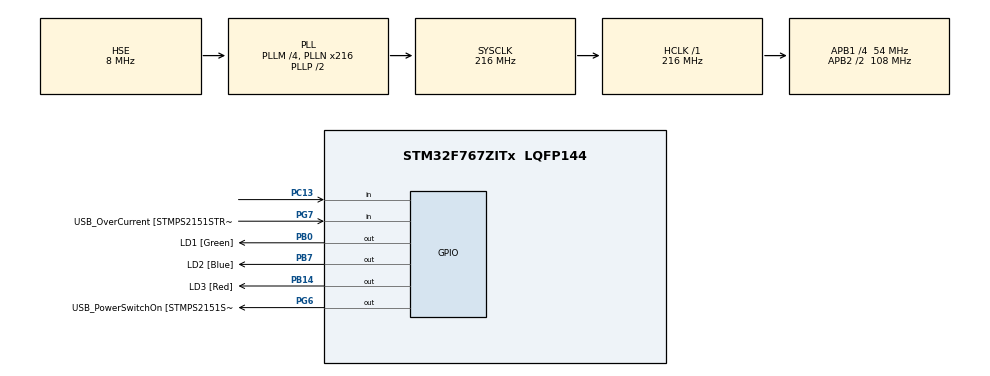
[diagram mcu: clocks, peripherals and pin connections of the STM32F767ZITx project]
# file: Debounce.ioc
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Mcu.Family=STM32F7
Mcu.Name=STM32F767ZITx
Mcu.Package=LQFP144
NVIC.PriorityGroup=NVIC_PRIORITYGROUP_4
NVIC.TIM6_DAC_IRQn=true\:0\:0\:false\:false\:true\:true\:true
PA13.GPIO_Label=TMS
PA13.Mode=Serial_Wire
PA13.Signal=SYS_JTMS-SWDIO
PA14.GPIO_Label=TCK
PA14.Mode=Serial_Wire
PA14.Signal=SYS_JTCK-SWCLK
PB0.GPIO_Label=LD1 [Green]
PB0.Signal=GPIO_Output
PB14.GPIO_Label=LD3 [Red]
PB14.Signal=GPIO_Output
PB7.GPIO_Label=LD2 [Blue]
PB7.Signal=GPIO_Output
PC13.Signal=GPIO_Input
PG6.GPIO_Label=USB_PowerSwitchOn [STMPS2151STR_EN]
PG6.Signal=GPIO_Output
PG7.GPIO_Label=USB_OverCurrent [STMPS2151STR_FAULT]
PG7.Signal=GPIO_Input
PH0/OSC_IN.GPIO_Label=MCO [STM32F103CBT6_PA8]
PH0/OSC_IN.Mode=HSE-External-Clock-Source
PH0/OSC_IN.Signal=RCC_OSC_IN
PH1/OSC_OUT.Mode=HSE-External-Clock-Source
PH1/OSC_OUT.Signal=RCC_OSC_OUT
ProjectManager.HeapSize=0x200
ProjectManager.StackSize=0x400
ProjectManager.TargetToolchain=MDK-ARM V5.27
RCC.48MHZClocksFreq_Value=24000000
RCC.AHBFreq_Value=216000000
RCC.APB1CLKDivider=RCC_HCLK_DIV4
RCC.APB1Freq_Value=54000000
RCC.APB1TimFreq_Value=108000000
RCC.APB2CLKDivider=RCC_HCLK_DIV2
RCC.APB2Freq_Value=108000000
RCC.APB2TimFreq_Value=216000000
RCC.CortexFreq_Value=216000000
RCC.HCLKFreq_Value=216000000
RCC.HSE_VALUE=8000000
RCC.HSI_VALUE=16000000
RCC.PLLM=4
RCC.PLLMUL=RCC_PLL_MUL9
RCC.PLLN=216
RCC.PLLQ=4
RCC.PLLSourceVirtual=RCC_PLLSOURCE_HSE
RCC.PRESCALERUSB=RCC_USBCLKSOURCE_PLL_DIV1_5
RCC.SYSCLKFreq_VALUE=216000000
RCC.SYSCLKSource=RCC_SYSCLKSOURCE_PLLCLK
RCC.SYSCLKSourceVirtual=RCC_SYSCLKSOURCE_PLLCLK
RCC.USBFreq_Value=108000000
RCC.VCOOutputFreq_Value=432000000
TIM6.Period=4000
TIM6.Prescaler=2699
TIM6.TIM_MasterOutputTrigger=TIM_TRGO_UPDATE
VP_TIM6_VS_ClockSourceINT.Mode=Enable_Timer
board=NUCLEO-F767ZI

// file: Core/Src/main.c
/* USER CODE BEGIN Header */
/**
  ******************************************************************************
  * @file           : main.c
  * @brief          : Main program body
  ******************************************************************************
  * @attention
  *
  * <h2><center>&copy; Copyright (c) 2021 STMicroelectronics.
  * All rights reserved.</center></h2>
  *
  * This software component is licensed by ST under BSD 3-Clause license,
  * the "License"; You may not use this file except in compliance with the
  * License. You may obtain a copy of the License at:
  *                        opensource.org/licenses/BSD-3-Clause
  *
  ******************************************************************************
  */
/* USER CODE END Header */
#include "main.h"
#include "tim.h"
#include "gpio.h"

/* USER CODE BEGIN Includes */
#include "debounce.h"
/* USER CODE END Includes */

/* USER CODE BEGIN PV */

ST_debounce button;
uint8_t button_output;

/* USER CODE END PV */

void SystemClock_Config(void);

int main(void)
{

  /* MCU Configuration--------------------------------------------------------*/

  /* Reset of all peripherals, Initializes the Flash interface and the Systick. */
  HAL_Init();

  /* Configure the system clock */
  SystemClock_Config();

  /* Initialize all configured peripherals */
  MX_GPIO_Init();
  MX_TIM6_Init();
  /* USER CODE BEGIN 2 */
	HAL_TIM_Base_Start_IT(&htim6);
	init_debounce_struct(&button,GPIOC, GPIO_PIN_13);
  /* USER CODE END 2 */

  /* Infinite loop */
  /* USER CODE BEGIN WHILE */
  while (1)
  {
		 if(button_output){
			HAL_GPIO_TogglePin(GPIOB,GPIO_PIN_7);
			 button_output=0;
		 }

    /* USER CODE END WHILE */

  }
}

void SystemClock_Config(void)
{
  RCC_OscInitTypeDef RCC_OscInitStruct = {0};
  RCC_ClkInitTypeDef RCC_ClkInitStruct = {0};

  /** Configure the main internal regulator output voltage
  */
  __HAL_RCC_PWR_CLK_ENABLE();
  __HAL_PWR_VOLTAGESCALING_CONFIG(PWR_REGULATOR_VOLTAGE_SCALE1);
  /** Initializes the RCC Oscillators according to the specified parameters
  * in the RCC_OscInitTypeDef structure.
  */
  RCC_OscInitStruct.OscillatorType = RCC_OSCILLATORTYPE_HSE;
  RCC_OscInitStruct.HSEState = RCC_HSE_BYPASS;
  RCC_OscInitStruct.PLL.PLLState = RCC_PLL_ON;
  RCC_OscInitStruct.PLL.PLLSource = RCC_PLLSOURCE_HSE;
  RCC_OscInitStruct.PLL.PLLM = 4;
  RCC_OscInitStruct.PLL.PLLN = 216;
  RCC_OscInitStruct.PLL.PLLP = RCC_PLLP_DIV2;
  RCC_OscInitStruct.PLL.PLLQ = 4;
  if (HAL_RCC_OscConfig(&RCC_OscInitStruct) != HAL_OK)
  {
    Error_Handler();
  }
  /** Activate the Over-Drive mode
  */
  if (HAL_PWREx_EnableOverDrive() != HAL_OK)
  {
    Error_Handler();
  }
  /** Initializes the CPU, AHB and APB buses clocks
  */
  RCC_ClkInitStruct.ClockType = RCC_CLOCKTYPE_HCLK|RCC_CLOCKTYPE_SYSCLK
                              |RCC_CLOCKTYPE_PCLK1|RCC_CLOCKTYPE_PCLK2;
  RCC_ClkInitStruct.SYSCLKSource = RCC_SYSCLKSOURCE_PLLCLK;
  RCC_ClkInitStruct.AHBCLKDivider = RCC_SYSCLK_DIV1;
  RCC_ClkInitStruct.APB1CLKDivider = RCC_HCLK_DIV4;
  RCC_ClkInitStruct.APB2CLKDivider = RCC_HCLK_DIV2;

  if (HAL_RCC_ClockConfig(&RCC_ClkInitStruct, FLASH_LATENCY_7) != HAL_OK)
  {
    Error_Handler();
  }
}

void Error_Handler(void)
{
  __disable_irq();
  while (1)
  {
  }
}

/************************ (C) COPYRIGHT STMicroelectronics *****END OF FILE****/
